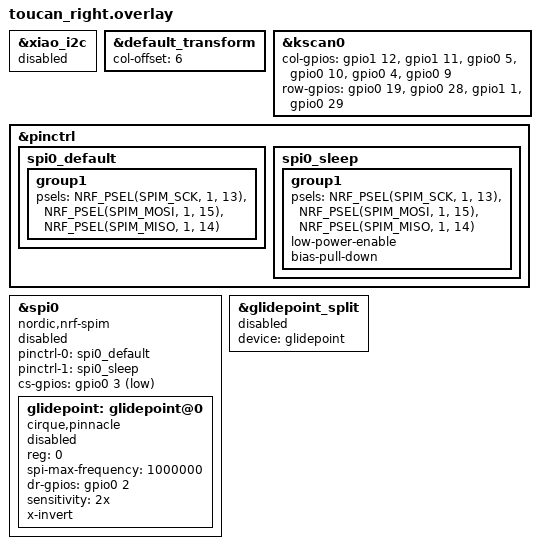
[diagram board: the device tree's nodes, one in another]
#include "toucan.dtsi"
#include <input/processors.dtsi>
#include <dt-bindings/zmk/input_transform.h>

&xiao_i2c {
    status = "disabled";
};

&default_transform {
    col-offset = <6>;
};

&kscan0 {
    col-gpios
    = <&gpio1 12 GPIO_ACTIVE_HIGH>
    , <&gpio1 11 GPIO_ACTIVE_HIGH>
    , <&gpio0 5 GPIO_ACTIVE_HIGH>
    , <&gpio0 10 GPIO_ACTIVE_HIGH>
    , <&gpio0 4 GPIO_ACTIVE_HIGH>
    , <&gpio0 9 GPIO_ACTIVE_HIGH>
    ;

    row-gpios
    = <&gpio0 19 (GPIO_ACTIVE_HIGH | GPIO_PULL_DOWN)>
    , <&gpio0 28 (GPIO_ACTIVE_HIGH | GPIO_PULL_DOWN)>
    , <&gpio1 1 (GPIO_ACTIVE_HIGH | GPIO_PULL_DOWN)>
    , <&gpio0 29 (GPIO_ACTIVE_HIGH | GPIO_PULL_DOWN)>
    ;
};

&pinctrl {
    spi0_default: spi0_default {
        group1 {
            psels = <NRF_PSEL(SPIM_SCK, 1, 13)>,
                <NRF_PSEL(SPIM_MOSI, 1, 15)>,
                <NRF_PSEL(SPIM_MISO, 1, 14)>;
        };
    };

     spi0_sleep: spi0_sleep {
        group1 {
            psels = <NRF_PSEL(SPIM_SCK, 1, 13)>,
                    <NRF_PSEL(SPIM_MOSI, 1, 15)>,
                    <NRF_PSEL(SPIM_MISO, 1, 14)>;
            low-power-enable;
            bias-pull-down; // minimize power leakage during sleep
        };
    };

};

&spi0 {
   compatible = "nordic,nrf-spim";
   // DEBUG: SPI bus disabled to remove the entire trackpad path from firmware
   // (no driver bind, no SPI activity, no DR GPIO interrupt config). Used to
   // isolate whether the right-half battery drain is the trackpad path or
   // something else. Revert this commit to restore normal operation.
   status = "disabled";
   pinctrl-0 = <&spi0_default>;
   pinctrl-1 = <&spi0_sleep>;
   pinctrl-names = "default", "sleep";
   cs-gpios = <&gpio0 3 (GPIO_ACTIVE_LOW | GPIO_PULL_UP)>;  // pull-up to ensure CS is !asserted when asleep
   glidepoint:  glidepoint@0 {
        compatible = "cirque,pinnacle";
        reg = <0>;
        spi-max-frequency = <1000000>;
        status = "disabled";  // DEBUG: see &spi0 comment above
        dr-gpios = <&gpio0 2 (GPIO_ACTIVE_HIGH)>;
        sensitivity = "2x";
        x-invert;

        // Pinnacle chip-level autosleep is intentionally disabled here.
        // CONFIG_ZMK_INPUT_PINNACLE_IDLE_SLEEPER (in toucan_right.conf) puts
        // the trackpad into standby when ZMK enters idle (30s of no input).
        // Enabling 'sleep;' as well would force ~400ms chip-level autosleep
        // between every touch — the idle sleeper then has to wake it on every
        // ACTIVE transition, costing power AND adding a 300ms gesture-start
        // delay. Pick one strategy; we picked the idle sleeper for better UX.
        // sleep;
    };
};

&glidepoint_split {
    // DEBUG: split input also disabled so nothing tries to forward trackpad
    // events over BLE. See &spi0 comment above.
    status = "disabled";
    device = <&glidepoint>;

    // Optional
    // input-processors = <&zip_xy_transform (INPUT_TRANSFORM_XY_SWAP | INPUT_TRANSFORM_X_INVERT | INPUT_TRANSFORM_Y_INVERT)>;
};
